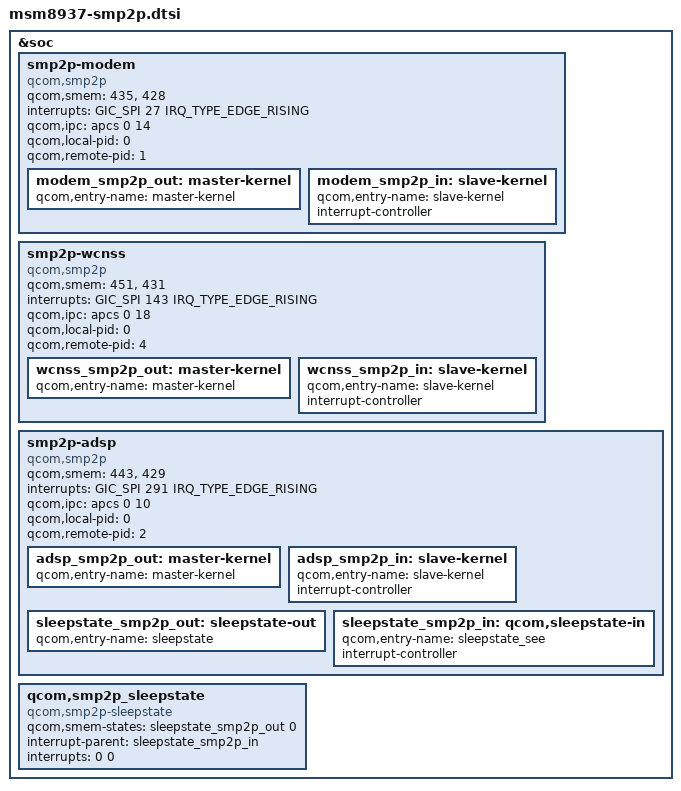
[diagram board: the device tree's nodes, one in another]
/* Copyright (c) 2015, 2018 The Linux Foundation. All rights reserved.
 *
 * This program is free software; you can redistribute it and/or modify
 * it under the terms of the GNU General Public License version 2 and
 * only version 2 as published by the Free Software Foundation.
 *
 * This program is distributed in the hope that it will be useful,
 * but WITHOUT ANY WARRANTY; without even the implied warranty of
 * MERCHANTABILITY or FITNESS FOR A PARTICULAR PURPOSE.  See the
 * GNU General Public License for more details.
 */
&soc {
	smp2p-modem {
		compatible = "qcom,smp2p";
		qcom,smem = <435>, <428>;
		interrupts = <GIC_SPI 27 IRQ_TYPE_EDGE_RISING>;
		qcom,ipc = <&apcs 0 14>;
		qcom,local-pid = <0>;
		qcom,remote-pid = <1>;

		modem_smp2p_out: master-kernel {
			qcom,entry-name = "master-kernel";
			#qcom,smem-state-cells = <1>;
		};

		modem_smp2p_in: slave-kernel {
			qcom,entry-name = "slave-kernel";
			interrupt-controller;
			#interrupt-cells = <2>;
		};
	};

	smp2p-wcnss {
		compatible = "qcom,smp2p";
		qcom,smem = <451>, <431>;
		interrupts = <GIC_SPI 143 IRQ_TYPE_EDGE_RISING>;
		qcom,ipc = <&apcs 0 18>;
		qcom,local-pid = <0>;
		qcom,remote-pid = <4>;

		wcnss_smp2p_out: master-kernel {
			qcom,entry-name = "master-kernel";
			#qcom,smem-state-cells = <1>;
		};

		wcnss_smp2p_in: slave-kernel {
			qcom,entry-name = "slave-kernel";
			interrupt-controller;
			#interrupt-cells = <2>;
		};
	};

	smp2p-adsp {
		compatible = "qcom,smp2p";
		qcom,smem = <443>, <429>;
		interrupts = <GIC_SPI 291 IRQ_TYPE_EDGE_RISING>;
		qcom,ipc = <&apcs 0 10>;
		qcom,local-pid = <0>;
		qcom,remote-pid = <2>;

		adsp_smp2p_out: master-kernel {
			qcom,entry-name = "master-kernel";
			#qcom,smem-state-cells = <1>;
		};

		adsp_smp2p_in: slave-kernel {
			qcom,entry-name = "slave-kernel";
			interrupt-controller;
			#interrupt-cells = <2>;
		};

		sleepstate_smp2p_out: sleepstate-out {
			qcom,entry-name = "sleepstate";
			#qcom,smem-state-cells = <1>;
		};

		sleepstate_smp2p_in: qcom,sleepstate-in {
			qcom,entry-name = "sleepstate_see";
			interrupt-controller;
			#interrupt-cells = <2>;
		};
	};

	qcom,smp2p_sleepstate {
		compatible = "qcom,smp2p-sleepstate";
		qcom,smem-states = <&sleepstate_smp2p_out 0>;
		interrupt-parent = <&sleepstate_smp2p_in>;
		interrupts = <0 0>;
		interrupt-names = "smp2p-sleepstate-in";
	};
};
